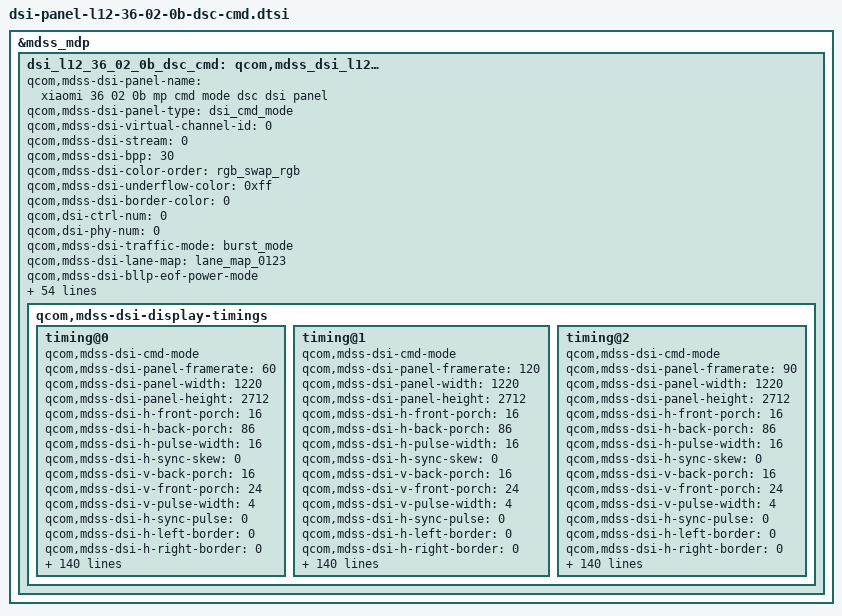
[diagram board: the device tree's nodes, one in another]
&mdss_mdp {
	dsi_l12_36_02_0b_dsc_cmd: qcom,mdss_dsi_l12_36_02_0b_dsc_cmd {
		qcom,mdss-dsi-panel-name = "xiaomi 36 02 0b mp cmd mode dsc dsi panel";
		qcom,mdss-dsi-panel-type = "dsi_cmd_mode";
		qcom,mdss-dsi-virtual-channel-id = <0>;
		qcom,mdss-dsi-stream = <0>;
		qcom,mdss-dsi-bpp = <30>;
		qcom,mdss-dsi-color-order = "rgb_swap_rgb";
		qcom,mdss-dsi-underflow-color = <0xff>;
		qcom,mdss-dsi-border-color = <0>;

		qcom,dsi-ctrl-num = <0>;
		qcom,dsi-phy-num = <0>;

		qcom,mdss-dsi-traffic-mode = "burst_mode";
		qcom,mdss-dsi-lane-map = "lane_map_0123";
		qcom,mdss-dsi-bllp-eof-power-mode;
		qcom,mdss-dsi-bllp-power-mode;
		qcom,mdss-dsi-lane-0-state;
		qcom,mdss-dsi-lane-1-state;
		qcom,mdss-dsi-lane-2-state;
		qcom,mdss-dsi-lane-3-state;
		qcom,mdss-dsi-dma-trigger = "trigger_sw";
		qcom,mdss-dsi-mdp-trigger = "none";
		qcom,mdss-dsi-reset-sequence =  <1 11>, <0 1>, <1 11>;
		qcom,mdss-pan-physical-width-dimension = <695>;
		qcom,mdss-pan-physical-height-dimension = <1545>;
		qcom,mdss-dsi-te-pin-select = <1>;
		qcom,mdss-dsi-wr-mem-start = <0x2c>;
		qcom,mdss-dsi-wr-mem-continue = <0x3c>;
		qcom,mdss-dsi-te-dcs-command = <1>;
		qcom,mdss-dsi-te-check-enable;
		qcom,mdss-dsi-te-using-te-pin;
		qcom,mdss-dsi-tx-eot-append;
		qcom,mdss-dsi-lp11-init;

		qcom,mdss-dsi-bl-inverted-dbv;
		qcom,bl-update-flag = "delay_until_first_frame";
		qcom,mdss-dsi-panel-mode-switch;

		qcom,mdss-dsi-panel-hdr-enabled;
		qcom,mdss-dsi-panel-hdr-color-primaries = <14500 15500 32000 17000 15500 30000 8000 3000>;
		qcom,mdss-dsi-panel-peak-brightness = <4200000>;
		qcom,mdss-dsi-panel-blackness-level = <3230>;
		qcom,mdss-dsi-dma-schedule-line = <1>;
		qcom,mdss-dsi-dma-schedule-window = <10>;

		qcom,mdss-dsi-display-timings {
			/* 60 Hz */
			timing@0{
				qcom,mdss-dsi-cmd-mode;
				qcom,mdss-dsi-panel-framerate = <60>;
				qcom,mdss-dsi-panel-width = <1220>;
				qcom,mdss-dsi-panel-height = <2712>;
				qcom,mdss-dsi-h-front-porch = <16>;
				qcom,mdss-dsi-h-back-porch = <86>;
				qcom,mdss-dsi-h-pulse-width = <16>;
				qcom,mdss-dsi-h-sync-skew = <0>;
				qcom,mdss-dsi-v-back-porch = <16>;
				qcom,mdss-dsi-v-front-porch = <24>;
				qcom,mdss-dsi-v-pulse-width = <4>;
				qcom,mdss-dsi-h-sync-pulse = <0>;
				qcom,mdss-dsi-h-left-border = <0>;
				qcom,mdss-dsi-h-right-border = <0>;
				qcom,mdss-dsi-v-top-border = <0>;
				qcom,mdss-dsi-v-bottom-border = <0>;
				qcom,mdss-dsi-panel-clockrate = <1100000000>;
				qcom,mdss-dsi-panel-jitter = <0x5 0x1>;
				qcom,mdss-mdp-transfer-time-us = <7300>;
				qcom,mdss-dsi-on-command = [
					/* common OD code */
					39 00 00 00 00 00 06 F0 55 AA 52 08 08
					39 00 00 40 00 00 06 E0 41 73 73 73 83
					39 00 00 40 00 00 16 E1
						00 00 00 00 00 00 00 00 00 00 00 00 00 00 00 00
						00 00 00 00 00
					39 00 00 40 00 00 16 E2
						80 EF 66 86 00 00 00 00 00 00 00 00 00 00 00 00
						00 00 02 01 00
					39 00 00 40 00 00 16 E3
						00 00 00 00 00 00 00 00 00 00 00 00 00 00 00 00
						00 00 00 00 00
					39 00 00 40 00 00 13 E4
						00 00 00 00 00 00 00 00 00 00 00 00 00 00 00 00
						00 00
					39 00 00 40 00 00 13 E5
						00 00 00 00 00 00 00 00 00 00 00 00 00 00 00 00
						00 00
					39 00 00 00 00 00 13 E6
						00 00 00 00 00 00 00 00 00 00 00 00 00 00 00 00
						00 00
					39 00 00 40 00 00 06 F0 55 AA 52 08 07
					15 00 00 40 00 00 02 6F 37
					39 00 00 40 00 00 04 B7 08 08 08
					39 00 00 40 00 00 06 F0 55 AA 52 08 00
					15 00 00 40 00 00 02 6F 37
					39 00 00 40 00 00 04 B7 08 08 08
					39 00 00 40 00 00 06 F0 55 AA 52 08 00
					15 00 00 40 00 00 02 6F 01
					15 00 00 40 00 00 02 C0 20
					39 00 00 40 00 00 06 F0 55 AA 52 08 08
					39 00 00 40 00 00 22 EA
						02 00 E0 00 E0 70 00 70 00 00 00 00 00 00 00 00
						00 00 00 00 00 00 00 00 00 00 00 00 00 00 00 00
						00
					15 00 00 40 00 00 02 6F 15
					39 00 00 40 00 00 07 EA 00 00 80 00 80 00
					39 00 00 40 00 00 06 F0 55 AA 52 08 08
					15 00 00 40 00 00 02 6F 21
					39 00 00 00 00 00 07 EA 00 00 00 00 00 00
					/* 60Hz OD code */
					39 00 00 40 00 00 06 F0 55 AA 52 08 08
					15 00 00 40 00 00 02 E0 01
					39 00 00 40 00 00 05 E2 88 E0 CC 0C
					15 00 00 40 00 00 02 6F 12
					39 00 00 40 00 00 03 E2 86 01
					39 00 00 40 00 00 09 EA 02 00 E0 00 E0 70 00 70
					15 00 00 40 00 00 02 6F 17
					39 00 00 00 00 00 04 EA 80 00 80
					/* Enable EMIT real-time Reset */
					39 00 00 40 00 00 06 F0 55 AA 52 08 00
					15 00 00 40 00 00 02 6F 13
					15 00 00 00 00 00 02 B2 4F
					/* Write time detection */
					39 00 00 40 00 00 05 FF AA 55 A5 81
					15 00 00 40 00 00 02 6F 19
					15 00 00 40 00 00 02 FB 00
					15 00 00 40 00 00 02 6F 05
					15 00 00 00 00 00 02 FE 34
					/* VGMP */
					39 00 00 40 00 00 05 FF AA 55 A5 80
					15 00 00 40 00 00 02 6F 1A
					15 00 00 40 00 00 02 F4 55
					15 00 00 40 00 00 02 6F 0F
					15 00 00 40 00 00 02 fc 00
					15 00 00 40 00 00 02 6F 09
					39 00 00 00 00 00 03 Fc FC F0
					/* SRAM */
					39 00 00 40 00 00 05 FF AA 55 A5 83
					15 00 00 40 00 00 02 6F 12
					15 00 00 00 00 00 02 FE 41
					/* GIR OFF */
					15 00 00 40 00 00 02 5F 01
					15 00 00 40 00 00 02 26 00
					15 00 00 00 00 00 02 17 10
					/* CASET/RASET Setting 1220*2712 */
					39 00 00 40 00 00 05 2A 00 00 04 C3
					39 00 00 00 00 00 05 2B 00 00 0A 97
					/* 60 Hz */
					15 00 00 00 00 00 02 2F 00
					/* TE ON */
					15 00 00 40 00 00 02 35 30
					39 00 00 40 00 00 03 44 00 00
					39 00 00 40 00 00 03 51 00 00
					15 00 00 40 00 00 02 6F 04
					39 00 00 40 00 00 03 51 03 FF
					15 00 00 00 00 00 02 53 20
					/* DSC Setting */
					15 00 00 40 00 00 02 90 03
					39 00 00 40 00 00 13 91
						AB 28 00 0C D2 00 02 4C 01 24 00 08 09 75 07 7B
						10 F0
					39 00 00 40 00 00 05 FF AA 55 A5 81
					15 00 00 40 00 00 02 6F 0B
					15 00 00 40 00 00 02 FD 80
					39 00 00 40 00 00 05 FF AA 55 A5 81
					15 00 00 40 00 00 02 6F 0E
					15 00 00 00 00 00 02 F5 00
					/* OSC=127.9525M */
					39 00 00 40 00 00 05 FF AA 55 A5 80
					15 00 00 40 00 00 02 6F 15
					39 00 00 40 00 00 03 F8 01 68
					15 00 00 40 00 00 02 6F 31
					39 00 00 40 00 00 03 F8 01 0E
					15 00 00 40 00 00 02 6F 01
					15 00 00 00 00 00 02 1F 06
					/* Video trim */
					39 00 00 40 00 00 05 FF AA 55 A5 80
					15 00 00 40 00 00 02 6F 31
					39 00 00 40 00 00 03 F8 01 0C
					39 00 00 40 00 00 05 FF AA 55 A5 80
					15 00 00 40 00 00 02 6F 15
					39 00 00 40 00 00 03 F8 01 5F
					39 00 00 40 00 00 06 F0 55 AA 52 08 01
					39 00 00 00 00 00 2A C3
						DD 06 22 11 FF 00 06 20 11 FF 00 04 01 11 05 95
						18 04 01 11 05 95 18 04 01 11 05 95 18 04 01 11
						05 95 18 04 01 11 05 95 18
					/* ESD Error Flag, Normal High, Error Low */
					39 00 00 40 00 00 06 F0 55 AA 52 08 00
					39 00 00 40 00 00 02 6F 01
					39 00 00 40 00 00 02 BE 45
					39 00 00 40 00 00 02 6F 05
					39 00 00 00 00 00 02 BE 88
					/* dimming step timing */
					39 01 00 40 00 00 06 F0 55 AA 52 08 00
					15 01 00 40 00 00 02 B2 09
					15 01 00 40 00 00 02 6F 05
					39 01 00 00 00 00 03 B2 08 08
					/* AOD Flicker Not P2 batch need to add*/
					39 00 00 40 00 00 06 F0 55 AA 52 08 00
					15 00 00 40 00 00 02 E2 40
					15 00 00 40 00 00 02 6F 57
					39 00 00 40 00 00 06 E2 FF FF FF FF FF
					15 00 00 40 00 00 02 6F 37
					39 00 00 00 00 00 05 E2 80 08 08 0C
					/* TM Dotted line */
					39 00 00 40 00 00 06 F0 55 AA 52 08 01
					15 00 00 00 00 00 02 DD 40
					/* TM-DSOP-OFF */
					39 00 00 40 00 00 06 F0 55 AA 52 08 00
					39 00 00 00 00 00 11 C6
						AD AA AA A3 AD AA AA A3 AD AA AA A3 AD AA AA A3
					/* Power Off Regulator Timing */
					39 00 00 40 00 00 05 FF AA 55 A5 80
					15 00 00 40 00 00 02 6F 0A
					39 00 00 40 00 00 04 F6 70 70 70
					15 00 00 40 00 00 02 6F 0E
					15 00 00 40 00 00 02 F6 70
					/* AOD On/Off Speed Up */
					15 00 00 40 00 00 02 6F 2D
					15 00 00 00 00 00 02 FC 44
					39 00 00 40 00 00 06 F0 55 AA 52 08 01
					15 00 00 40 00 00 02 6F 01
					39 00 00 40 00 00 05 D2 00 00 00 20
					39 00 00 40 00 00 04 E4 80 05 5C
					15 00 00 40 00 00 02 6F 07
					39 00 00 40 00 00 03 E4 05 5C
					15 00 00 40 00 00 02 6F 0A
					39 00 00 40 00 00 04 E4 80 05 5C
					15 00 00 40 00 00 02 6F 21
					39 00 00 40 00 00 04 D8 60 60 60
					/* VGL_REG shift 1/2 Frame */
					15 00 00 40 00 00 02 6F 1E
					15 00 00 40 00 00 02 D8 24
					/* //PVDD&PVEE OFF Shift 1 Frame */
					15 00 00 00 00 00 02 CD 61
					/* GOA power on/off Timing */
					39 00 00 40 00 00 06 F0 55 AA 52 08 05
					39 00 00 40 00 00 03 B3 84 85
					39 00 00 40 00 00 03 B5 84 85
					39 00 00 40 00 00 05 B7 84 00 00 84
					39 00 00 00 00 00 05 B8 84 00 00 84
					/* Power Off Frame */
					39 00 00 40 00 00 06 F0 55 AA 52 08 00
					15 00 00 40 00 00 02 6F 07
					39 00 00 00 00 00 04 CA 08 06 58
					/* Display on */
					05 00 00 00 78 00 02 11 00
					05 00 00 00 00 00 02 29 00
				];
				qcom,mdss-dsi-off-command = [
					05 00 00 00 00 00 02 28 00
					05 00 00 00 64 00 02 10 00
				];
				qcom,mdss-dsi-on-command-state = "dsi_lp_mode";
				qcom,mdss-dsi-off-command-state = "dsi_lp_mode";

				qcom,mdss-dsi-timing-switch-command = [
					/* 60 Hz */
					15 00 00 00 00 00 02 2F 00
					/* 60Hz OD code */
					39 00 00 40 00 00 06 F0 55 AA 52 08 08
					15 00 00 40 00 00 02 E0 01
					39 00 00 40 00 00 05 E2 88 E0 CC 0C
					15 00 00 40 00 00 02 6F 12
					39 00 00 40 00 00 03 E2 86 01
					39 00 00 40 00 00 09 EA 02 00 E0 00 E0 70 00 70
					15 00 00 40 00 00 02 6F 17
					39 00 00 00 00 00 04 EA 80 00 80
				];
				qcom,mdss-dsi-timing-switch-command-update = <0x2F 0 1>;
				qcom,mdss-dsi-timing-switch-command-state = "dsi_hs_mode";

				qcom,mdss-dsi-nolp-command = [
					/* Enable osc trim */
					39 00 00 00 00 00 06 F0 55 AA 52 08 01
					15 00 00 00 00 00 02 C3 DD
					/*AOD Mode off*/
					15 00 00 00 00 00 02 65 00
					15 00 00 00 00 00 02 38 00
					39 00 00 00 00 00 07 51 00 00 00 00 03 FF
					15 00 00 00 00 00 02 2C 00
					/* ERR Flag enable */
					39 00 00 00 00 00 06 F0 55 AA 52 08 00
					39 00 00 00 00 00 02 6F 01
					39 00 00 00 00 00 02 BE 45
				];
				qcom,mdss-dsi-nolp-command-state = "dsi_lp_mode";

				qcom,compression-mode = "dsc";
				qcom,mdss-dsc-config-by-manufacture-cmd;
				qcom,mdss-dsc-version = <0x11>;
				qcom,mdss-dsc-scr-version = <0x1>;
				qcom,mdss-dsc-slice-height = <12>;
				qcom,mdss-dsc-slice-width = <610>;
				qcom,mdss-dsc-slice-per-pkt = <2>;
				qcom,mdss-dsc-bit-per-component = <10>;
				qcom,mdss-dsc-bit-per-pixel = <8>;
				qcom,mdss-dsc-block-prediction-enable;
			};
			/* 120 Hz */
			timing@1{
				qcom,mdss-dsi-cmd-mode;
				qcom,mdss-dsi-panel-framerate = <120>;
				qcom,mdss-dsi-panel-width = <1220>;
				qcom,mdss-dsi-panel-height = <2712>;
				qcom,mdss-dsi-h-front-porch = <16>;
				qcom,mdss-dsi-h-back-porch = <86>;
				qcom,mdss-dsi-h-pulse-width = <16>;
				qcom,mdss-dsi-h-sync-skew = <0>;
				qcom,mdss-dsi-v-back-porch = <16>;
				qcom,mdss-dsi-v-front-porch = <24>;
				qcom,mdss-dsi-v-pulse-width = <4>;
				qcom,mdss-dsi-h-sync-pulse = <0>;
				qcom,mdss-dsi-h-left-border = <0>;
				qcom,mdss-dsi-h-right-border = <0>;
				qcom,mdss-dsi-v-top-border = <0>;
				qcom,mdss-dsi-v-bottom-border = <0>;
				qcom,mdss-dsi-panel-clockrate = <1100000000>;
				qcom,mdss-dsi-panel-jitter = <0x5 0x1>;
				qcom,mdss-mdp-transfer-time-us = <7300>;
				qcom,mdss-dsi-on-command = [
					/* common OD code */
					39 00 00 00 00 00 06 F0 55 AA 52 08 08
					39 00 00 40 00 00 06 E0 41 73 73 73 83
					39 00 00 40 00 00 16 E1
						00 00 00 00 00 00 00 00 00 00 00 00 00 00 00 00
						00 00 00 00 00
					39 00 00 40 00 00 16 E2
						80 EF 66 86 00 00 00 00 00 00 00 00 00 00 00 00
						00 00 02 01 00
					39 00 00 40 00 00 16 E3
						00 00 00 00 00 00 00 00 00 00 00 00 00 00 00 00
						00 00 00 00 00
					39 00 00 40 00 00 13 E4
						00 00 00 00 00 00 00 00 00 00 00 00 00 00 00 00
						00 00
					39 00 00 40 00 00 13 E5
						00 00 00 00 00 00 00 00 00 00 00 00 00 00 00 00
						00 00
					39 00 00 00 00 00 13 E6
						00 00 00 00 00 00 00 00 00 00 00 00 00 00 00 00
						00 00
					39 00 00 40 00 00 06 F0 55 AA 52 08 07
					15 00 00 40 00 00 02 6F 37
					39 00 00 40 00 00 04 B7 08 08 08
					39 00 00 40 00 00 06 F0 55 AA 52 08 00
					15 00 00 40 00 00 02 6F 37
					39 00 00 40 00 00 04 B7 08 08 08
					39 00 00 40 00 00 06 F0 55 AA 52 08 00
					15 00 00 40 00 00 02 6F 01
					15 00 00 40 00 00 02 C0 20
					39 00 00 40 00 00 06 F0 55 AA 52 08 08
					39 00 00 40 00 00 22 EA
						02 00 E0 00 E0 70 00 70 00 00 00 00 00 00 00 00
						00 00 00 00 00 00 00 00 00 00 00 00 00 00 00 00
						00
					15 00 00 40 00 00 02 6F 15
					39 00 00 40 00 00 07 EA 00 00 80 00 80 00
					39 00 00 40 00 00 06 F0 55 AA 52 08 08
					15 00 00 40 00 00 02 6F 21
					39 00 00 00 00 00 07 EA 00 00 00 00 00 00
					/* 120Hz OD code */
					39 00 00 40 00 00 06 F0 55 AA 52 08 08
					15 00 00 40 00 00 02 E0 01
					39 00 00 40 00 00 05 E2 D6 4E 84 88
					15 00 00 40 00 00 02 6F 12
					39 00 00 40 00 00 03 E2 FD 03
					39 00 00 40 00 00 09 EA 02 00 E0 00 E0 80 00 80
					15 00 00 40 00 00 02 6F 17
					39 00 00 00 00 00 04 EA 38 00 38
					/* Enable EMIT real-time Reset */
					39 00 00 40 00 00 06 F0 55 AA 52 08 00
					15 00 00 40 00 00 02 6F 13
					15 00 00 00 00 00 02 B2 4F
					/* Write time detection */
					39 00 00 40 00 00 05 FF AA 55 A5 81
					15 00 00 40 00 00 02 6F 19
					15 00 00 40 00 00 02 FB 00
					15 00 00 40 00 00 02 6F 05
					15 00 00 00 00 00 02 FE 34
					/* VGMP */
					39 00 00 40 00 00 05 FF AA 55 A5 80
					15 00 00 40 00 00 02 6F 1A
					15 00 00 40 00 00 02 F4 55
					15 00 00 40 00 00 02 6F 0F
					15 00 00 40 00 00 02 fc 00
					15 00 00 40 00 00 02 6F 09
					39 00 00 00 00 00 03 Fc FC F0
					/* SRAM */
					39 00 00 40 00 00 05 FF AA 55 A5 83
					15 00 00 40 00 00 02 6F 12
					15 00 00 00 00 00 02 FE 41
					/* GIR OFF */
					15 00 00 40 00 00 02 5F 01
					15 00 00 40 00 00 02 26 00
					15 00 00 00 00 00 02 17 10
					/* CASET/RASET Setting 1220*2712 */
					39 00 00 40 00 00 05 2A 00 00 04 C3
					39 00 00 00 00 00 05 2B 00 00 0A 97
					/* 120 Hz */
					15 00 00 00 00 00 02 2F 02
					/* TE ON */
					15 00 00 40 00 00 02 35 30
					39 00 00 40 00 00 03 44 00 00
					39 00 00 40 00 00 03 51 00 00
					15 00 00 40 00 00 02 6F 04
					39 00 00 40 00 00 03 51 03 FF
					15 00 00 00 00 00 02 53 20
					/* DSC Setting */
					15 00 00 40 00 00 02 90 03
					39 00 00 40 00 00 13 91
						AB 28 00 0C D2 00 02 4C 01 24 00 08 09 75 07 7B
						10 F0
					39 00 00 40 00 00 05 FF AA 55 A5 81
					15 00 00 40 00 00 02 6F 0B
					15 00 00 40 00 00 02 FD 80
					39 00 00 40 00 00 05 FF AA 55 A5 81
					15 00 00 40 00 00 02 6F 0E
					15 00 00 00 00 00 02 F5 00
					/* OSC=127.9525M */
					39 00 00 40 00 00 05 FF AA 55 A5 80
					15 00 00 40 00 00 02 6F 15
					39 00 00 40 00 00 03 F8 01 68
					15 00 00 40 00 00 02 6F 31
					39 00 00 40 00 00 03 F8 01 0E
					15 00 00 40 00 00 02 6F 01
					15 00 00 00 00 00 02 1F 06
					/* Video trim */
					39 00 00 40 00 00 05 FF AA 55 A5 80
					15 00 00 40 00 00 02 6F 31
					39 00 00 40 00 00 03 F8 01 0C
					39 00 00 40 00 00 05 FF AA 55 A5 80
					15 00 00 40 00 00 02 6F 15
					39 00 00 40 00 00 03 F8 01 5F
					39 00 00 40 00 00 06 F0 55 AA 52 08 01
					39 00 00 00 00 00 2A C3
						DD 06 22 11 FF 00 06 20 11 FF 00 04 01 11 05 95
						18 04 01 11 05 95 18 04 01 11 05 95 18 04 01 11
						05 95 18 04 01 11 05 95 18
					/* ESD Error Flag, Normal High, Error Low */
					39 00 00 40 00 00 06 F0 55 AA 52 08 00
					39 00 00 40 00 00 02 6F 01
					39 00 00 40 00 00 02 BE 45
					39 00 00 40 00 00 02 6F 05
					39 00 00 00 00 00 02 BE 88
					/* dimming step timing */
					39 00 00 40 00 00 06 F0 55 AA 52 08 00
					15 00 00 40 00 00 02 B2 09
					15 00 00 40 00 00 02 6F 05
					39 00 00 00 00 00 03 B2 08 08
					/* AOD Flicker Not P2 batch need to add*/
					39 00 00 40 00 00 06 F0 55 AA 52 08 00
					15 00 00 40 00 00 02 E2 40
					15 00 00 40 00 00 02 6F 57
					39 00 00 40 00 00 06 E2 FF FF FF FF FF
					15 00 00 40 00 00 02 6F 37
					39 00 00 00 00 00 05 E2 80 08 08 0C
					/* TM Dotted line */
					39 00 00 40 00 00 06 F0 55 AA 52 08 01
					15 00 00 00 00 00 02 DD 40
					/* TM-DSOP-OFF */
					39 00 00 40 00 00 06 F0 55 AA 52 08 00
					39 00 00 00 00 00 11 C6
						AD AA AA A3 AD AA AA A3 AD AA AA A3 AD AA AA A3
					/* Power Off Regulator Timing */
					39 00 00 40 00 00 05 FF AA 55 A5 80
					15 00 00 40 00 00 02 6F 0A
					39 00 00 40 00 00 04 F6 70 70 70
					15 00 00 40 00 00 02 6F 0E
					15 00 00 40 00 00 02 F6 70
					/* AOD On/Off Speed Up */
					15 00 00 40 00 00 02 6F 2D
					15 00 00 00 00 00 02 FC 44
					39 00 00 40 00 00 06 F0 55 AA 52 08 01
					15 00 00 40 00 00 02 6F 01
					39 00 00 40 00 00 05 D2 00 00 00 20
					39 00 00 40 00 00 04 E4 80 05 5C
					15 00 00 40 00 00 02 6F 07
					39 00 00 40 00 00 03 E4 05 5C
					15 00 00 40 00 00 02 6F 0A
					39 00 00 40 00 00 04 E4 80 05 5C
					15 00 00 40 00 00 02 6F 21
					39 00 00 40 00 00 04 D8 60 60 60
					/* VGL_REG shift 1/2 Frame */
					15 00 00 40 00 00 02 6F 1E
					15 00 00 40 00 00 02 D8 24
					/* //PVDD&PVEE OFF Shift 1 Frame */
					15 00 00 00 00 00 02 CD 61
					/* GOA power on/off Timing */
					39 00 00 40 00 00 06 F0 55 AA 52 08 05
					39 00 00 40 00 00 03 B3 84 85
					39 00 00 40 00 00 03 B5 84 85
					39 00 00 40 00 00 05 B7 84 00 00 84
					39 00 00 00 00 00 05 B8 84 00 00 84
					/* Power Off Frame */
					39 00 00 40 00 00 06 F0 55 AA 52 08 00
					15 00 00 40 00 00 02 6F 07
					39 00 00 00 00 00 04 CA 08 06 58
					/* Display on */
					05 00 00 00 78 00 02 11 00
					05 00 00 00 00 00 02 29 00
				];
				qcom,mdss-dsi-off-command = [
					05 00 00 00 00 00 02 28 00
					05 00 00 00 64 00 02 10 00
				];
				qcom,mdss-dsi-on-command-state = "dsi_lp_mode";
				qcom,mdss-dsi-off-command-state = "dsi_lp_mode";

				qcom,mdss-dsi-timing-switch-command = [
					/* 120 Hz */
					15 00 00 00 00 00 02 2F 02
					/* 120Hz OD code */
					39 00 00 40 00 00 06 F0 55 AA 52 08 08
					15 00 00 40 00 00 02 E0 01
					39 00 00 40 00 00 05 E2 D6 4E 84 88
					15 00 00 40 00 00 02 6F 12
					39 00 00 40 00 00 03 E2 FD 03
					39 00 00 40 00 00 09 EA 02 00 E0 00 E0 80 00 80
					15 00 00 40 00 00 02 6F 17
					39 00 00 00 00 00 04 EA 38 00 38
				];
				qcom,mdss-dsi-timing-switch-command-update = <0x2F 0 1>;
				qcom,mdss-dsi-timing-switch-command-state = "dsi_hs_mode";

				qcom,mdss-dsi-nolp-command = [
					/* Enable osc trim */
					39 00 00 00 00 00 06 F0 55 AA 52 08 01
					15 00 00 00 00 00 02 C3 DD
					/*AOD Mode off*/
					15 00 00 00 00 00 02 65 00
					15 00 00 00 00 00 02 38 00
					39 00 00 00 00 00 07 51 00 00 00 00 03 FF
					15 00 00 00 00 00 02 2C 00
					/* ERR Flag enable */
					39 00 00 00 00 00 06 F0 55 AA 52 08 00
					39 00 00 00 00 00 02 6F 01
					39 00 00 00 00 00 02 BE 45
				];
				qcom,mdss-dsi-nolp-command-state = "dsi_lp_mode";

				qcom,compression-mode = "dsc";
				qcom,mdss-dsc-config-by-manufacture-cmd;
				qcom,mdss-dsc-version = <0x11>;
				qcom,mdss-dsc-scr-version = <0x1>;
				qcom,mdss-dsc-slice-height = <12>;
				qcom,mdss-dsc-slice-width = <610>;
				qcom,mdss-dsc-slice-per-pkt = <2>;
				qcom,mdss-dsc-bit-per-component = <10>;
				qcom,mdss-dsc-bit-per-pixel = <8>;
				qcom,mdss-dsc-block-prediction-enable;
			};
           	/* 90 Hz */
			timing@2{
				qcom,mdss-dsi-cmd-mode;
				qcom,mdss-dsi-panel-framerate = <90>;
				qcom,mdss-dsi-panel-width = <1220>;
				qcom,mdss-dsi-panel-height = <2712>;
				qcom,mdss-dsi-h-front-porch = <16>;
				qcom,mdss-dsi-h-back-porch = <86>;
				qcom,mdss-dsi-h-pulse-width = <16>;
				qcom,mdss-dsi-h-sync-skew = <0>;
				qcom,mdss-dsi-v-back-porch = <16>;
				qcom,mdss-dsi-v-front-porch = <24>;
				qcom,mdss-dsi-v-pulse-width = <4>;
				qcom,mdss-dsi-h-sync-pulse = <0>;
				qcom,mdss-dsi-h-left-border = <0>;
				qcom,mdss-dsi-h-right-border = <0>;
				qcom,mdss-dsi-v-top-border = <0>;
				qcom,mdss-dsi-v-bottom-border = <0>;
				qcom,mdss-dsi-panel-clockrate = <1100000000>;
				qcom,mdss-dsi-panel-jitter = <0x5 0x1>;
				qcom,mdss-mdp-transfer-time-us = <7300>;
				qcom,mdss-dsi-on-command = [
					/* common OD code */
					39 00 00 00 00 00 06 F0 55 AA 52 08 08
					39 00 00 40 00 00 06 E0 41 73 73 73 83
					39 00 00 40 00 00 16 E1
						00 00 00 00 00 00 00 00 00 00 00 00 00 00 00 00
						00 00 00 00 00
					39 00 00 40 00 00 16 E2
						80 EF 66 86 00 00 00 00 00 00 00 00 00 00 00 00
						00 00 02 01 00
					39 00 00 40 00 00 16 E3
						00 00 00 00 00 00 00 00 00 00 00 00 00 00 00 00
						00 00 00 00 00
					39 00 00 40 00 00 13 E4
						00 00 00 00 00 00 00 00 00 00 00 00 00 00 00 00
						00 00
					39 00 00 40 00 00 13 E5
						00 00 00 00 00 00 00 00 00 00 00 00 00 00 00 00
						00 00
					39 00 00 00 00 00 13 E6
						00 00 00 00 00 00 00 00 00 00 00 00 00 00 00 00
						00 00
					39 00 00 40 00 00 06 F0 55 AA 52 08 07
					15 00 00 40 00 00 02 6F 37
					39 00 00 40 00 00 04 B7 08 08 08
					39 00 00 40 00 00 06 F0 55 AA 52 08 00
					15 00 00 40 00 00 02 6F 37
					39 00 00 40 00 00 04 B7 08 08 08
					39 00 00 40 00 00 06 F0 55 AA 52 08 00
					15 00 00 40 00 00 02 6F 01
					15 00 00 40 00 00 02 C0 20
					39 00 00 40 00 00 06 F0 55 AA 52 08 08
					39 00 00 40 00 00 22 EA
						02 00 E0 00 E0 70 00 70 00 00 00 00 00 00 00 00
						00 00 00 00 00 00 00 00 00 00 00 00 00 00 00 00
						00
					15 00 00 40 00 00 02 6F 15
					39 00 00 40 00 00 07 EA 00 00 80 00 80 00
					39 00 00 40 00 00 06 F0 55 AA 52 08 08
					15 00 00 40 00 00 02 6F 21
					39 00 00 00 00 00 07 EA 00 00 00 00 00 00
					/* 90Hz OD code */
					39 00 00 40 00 00 06 F0 55 AA 52 08 08
					15 00 00 40 00 00 02 E0 01
					39 00 00 40 00 00 05 E2 42 EE 04 20
					15 00 00 40 00 00 02 6F 12
					39 00 00 40 00 00 03 E2 FD 03
					39 00 00 40 00 00 09 EA 02 00 B8 00 B8 58 00 58
					15 00 00 40 00 00 02 6F 17
					39 00 00 00 00 00 04 EA 48 00 48
					/* Enable EMIT real-time Reset */
					39 00 00 40 00 00 06 F0 55 AA 52 08 00
					15 00 00 40 00 00 02 6F 13
					15 00 00 00 00 00 02 B2 4F
					/* Write time detection */
					39 00 00 40 00 00 05 FF AA 55 A5 81
					15 00 00 40 00 00 02 6F 19
					15 00 00 40 00 00 02 FB 00
					15 00 00 40 00 00 02 6F 05
					15 00 00 00 00 00 02 FE 34
					/* VGMP */
					39 00 00 40 00 00 05 FF AA 55 A5 80
					15 00 00 40 00 00 02 6F 1A
					15 00 00 40 00 00 02 F4 55
					15 00 00 40 00 00 02 6F 0F
					15 00 00 40 00 00 02 fc 00
					15 00 00 40 00 00 02 6F 09
					39 00 00 00 00 00 03 Fc FC F0
					/* SRAM */
					39 00 00 40 00 00 05 FF AA 55 A5 83
					15 00 00 40 00 00 02 6F 12
					15 00 00 00 00 00 02 FE 41
					/* GIR OFF */
					15 00 00 40 00 00 02 5F 01
					15 00 00 40 00 00 02 26 00
					15 00 00 00 00 00 02 17 10
					/* CASET/RASET Setting 1220*2712 */
					39 00 00 40 00 00 05 2A 00 00 04 C3
					39 00 00 00 00 00 05 2B 00 00 0A 97
					/* 90 Hz */
					15 00 00 00 00 00 02 2F 01
					/* TE ON */
					15 00 00 40 00 00 02 35 30
					39 00 00 40 00 00 03 44 00 00
					39 00 00 40 00 00 03 51 00 00
					15 00 00 40 00 00 02 6F 04
					39 00 00 40 00 00 03 51 03 FF
					15 00 00 00 00 00 02 53 20
					/* DSC Setting */
					15 00 00 40 00 00 02 90 03
					39 00 00 40 00 00 13 91
						AB 28 00 0C D2 00 02 4C 01 24 00 08 09 75 07 7B
						10 F0
					39 00 00 40 00 00 05 FF AA 55 A5 81
					15 00 00 40 00 00 02 6F 0B
					15 00 00 40 00 00 02 FD 80
					39 00 00 40 00 00 05 FF AA 55 A5 81
					15 00 00 40 00 00 02 6F 0E
					15 00 00 00 00 00 02 F5 00
					/* OSC=127.9525M */
					39 00 00 40 00 00 05 FF AA 55 A5 80
					15 00 00 40 00 00 02 6F 15
					39 00 00 40 00 00 03 F8 01 68
					15 00 00 40 00 00 02 6F 31
					39 00 00 40 00 00 03 F8 01 0E
					15 00 00 40 00 00 02 6F 01
					15 00 00 00 00 00 02 1F 06
					/* Video trim */
					39 00 00 40 00 00 05 FF AA 55 A5 80
					15 00 00 40 00 00 02 6F 31
					39 00 00 40 00 00 03 F8 01 0C
					39 00 00 40 00 00 05 FF AA 55 A5 80
					15 00 00 40 00 00 02 6F 15
					39 00 00 40 00 00 03 F8 01 5F
					39 00 00 40 00 00 06 F0 55 AA 52 08 01
					39 00 00 00 00 00 2A C3
						DD 06 22 11 FF 00 06 20 11 FF 00 04 01 11 05 95
						18 04 01 11 05 95 18 04 01 11 05 95 18 04 01 11
						05 95 18 04 01 11 05 95 18
					/* ESD Error Flag, Normal High, Error Low */
					39 00 00 40 00 00 06 F0 55 AA 52 08 00
					39 00 00 40 00 00 02 6F 01
					39 00 00 40 00 00 02 BE 45
					39 00 00 40 00 00 02 6F 05
					39 00 00 00 00 00 02 BE 88
					/* dimming step timing */
					39 01 00 40 00 00 06 F0 55 AA 52 08 00
					15 01 00 40 00 00 02 B2 09
					15 01 00 40 00 00 02 6F 05
					39 01 00 00 00 00 03 B2 08 08
					/* AOD Flicker Not P2 batch need to add*/
					39 00 00 40 00 00 06 F0 55 AA 52 08 00
					15 00 00 40 00 00 02 E2 40
					15 00 00 40 00 00 02 6F 57
					39 00 00 40 00 00 06 E2 FF FF FF FF FF
					15 00 00 40 00 00 02 6F 37
					39 00 00 00 00 00 05 E2 80 08 08 0C
					/* TM Dotted line */
					39 00 00 40 00 00 06 F0 55 AA 52 08 01
					15 00 00 00 00 00 02 DD 40
					/* TM-DSOP-OFF */
					39 00 00 40 00 00 06 F0 55 AA 52 08 00
					39 00 00 00 00 00 11 C6
						AD AA AA A3 AD AA AA A3 AD AA AA A3 AD AA AA A3
					/* Power Off Regulator Timing */
					39 00 00 40 00 00 05 FF AA 55 A5 80
					15 00 00 40 00 00 02 6F 0A
					39 00 00 40 00 00 04 F6 70 70 70
					15 00 00 40 00 00 02 6F 0E
					15 00 00 40 00 00 02 F6 70
					/* AOD On/Off Speed Up */
					15 00 00 40 00 00 02 6F 2D
					15 00 00 00 00 00 02 FC 44
					39 00 00 40 00 00 06 F0 55 AA 52 08 01
					15 00 00 40 00 00 02 6F 01
					39 00 00 40 00 00 05 D2 00 00 00 20
					39 00 00 40 00 00 04 E4 80 05 5C
					15 00 00 40 00 00 02 6F 07
					39 00 00 40 00 00 03 E4 05 5C
					15 00 00 40 00 00 02 6F 0A
					39 00 00 40 00 00 04 E4 80 05 5C
					15 00 00 40 00 00 02 6F 21
					39 00 00 40 00 00 04 D8 60 60 60
					/* VGL_REG shift 1/2 Frame */
					15 00 00 40 00 00 02 6F 1E
					15 00 00 40 00 00 02 D8 24
					/* //PVDD&PVEE OFF Shift 1 Frame */
					15 00 00 00 00 00 02 CD 61
					/* GOA power on/off Timing */
					39 00 00 40 00 00 06 F0 55 AA 52 08 05
					39 00 00 40 00 00 03 B3 84 85
					39 00 00 40 00 00 03 B5 84 85
					39 00 00 40 00 00 05 B7 84 00 00 84
					39 00 00 00 00 00 05 B8 84 00 00 84
					/* Power Off Frame */
					39 00 00 40 00 00 06 F0 55 AA 52 08 00
					15 00 00 40 00 00 02 6F 07
					39 00 00 00 00 00 04 CA 08 06 58
					/* Display on */
					05 00 00 00 78 00 02 11 00
					05 00 00 00 00 00 02 29 00
				];
				qcom,mdss-dsi-off-command = [
					05 00 00 00 00 00 02 28 00
					05 00 00 00 64 00 02 10 00
				];
				qcom,mdss-dsi-on-command-state = "dsi_lp_mode";
				qcom,mdss-dsi-off-command-state = "dsi_lp_mode";

				qcom,mdss-dsi-timing-switch-command = [
					/* 90 Hz */
					15 00 00 00 00 00 02 2F 01
					/* 90Hz OD code */
					39 00 00 40 00 00 06 F0 55 AA 52 08 08
					15 00 00 40 00 00 02 E0 01
					39 00 00 40 00 00 05 E2 42 EE 04 20
					15 00 00 40 00 00 02 6F 12
					39 00 00 40 00 00 03 E2 FD 03
					39 00 00 40 00 00 09 EA 02 00 B8 00 B8 58 00 58
					15 00 00 40 00 00 02 6F 17
					39 00 00 00 00 00 04 EA 48 00 48
				];
				qcom,mdss-dsi-timing-switch-command-update = <0x2F 0 1>;
				qcom,mdss-dsi-timing-switch-command-state = "dsi_hs_mode";

				qcom,mdss-dsi-nolp-command = [
					/* Enable osc trim */
					39 00 00 00 00 00 06 F0 55 AA 52 08 01
					15 00 00 00 00 00 02 C3 DD
					/*AOD Mode off*/
					15 00 00 00 00 00 02 65 00
					15 00 00 00 00 00 02 38 00
					39 00 00 00 00 00 07 51 00 00 00 00 03 FF
					15 00 00 00 00 00 02 2C 00
					/* ERR Flag enable */
					39 00 00 00 00 00 06 F0 55 AA 52 08 00
					39 00 00 00 00 00 02 6F 01
					39 00 00 00 00 00 02 BE 45
				];
				qcom,mdss-dsi-nolp-command-state = "dsi_lp_mode";

				qcom,compression-mode = "dsc";
				qcom,mdss-dsc-config-by-manufacture-cmd;
				qcom,mdss-dsc-version = <0x11>;
				qcom,mdss-dsc-scr-version = <0x1>;
				qcom,mdss-dsc-slice-height = <12>;
				qcom,mdss-dsc-slice-width = <610>;
				qcom,mdss-dsc-slice-per-pkt = <2>;
				qcom,mdss-dsc-bit-per-component = <10>;
				qcom,mdss-dsc-bit-per-pixel = <8>;
				qcom,mdss-dsc-block-prediction-enable;
			};
		};
	};
};

&dsi_l12_36_02_0b_dsc_cmd {
	mi,panel-id = <0x004C3132 0x00360200>;

	/* IRQF_ONESHOT | IRQF_TRIGGER_LOW */
	mi,esd-err-irq-gpio = <&tlmm 116 0x2008>;

	mi,thermal-dimming-flag;
	mi,panel-on-dimming-delay = <120>;
	mi,dimming-need-update-speed;
	mi,dimming-node = <0 200 450 800 4095>;

	mi,max-brightness-clone = <4095>;
	mi,normal-max-brightness-clone = <2047>;
	mi,mdss-dsi-fac-bl-max-level = <2047>;
	mi,mdss-fac-brightness-max-level = <2047>;
	mi,hbm-bl-min-level = <1>;
	mi,hbm-bl-max-level = <2047>;

	mi,local-hbm-enabled;
	mi,local-hbm-white-1000nit-update-flag;
	mi,local-hbm-white-110nit-update-flag;
	mi,local-hbm-alpha-ctrl-aa-area;
	mi,local-hbm-ctrl-df-reg;

	mi,doze-hbm-dbv-level = <252>;
	mi,doze-lbm-dbv-level = <20>;
	mi,ddic-round-corner-enabled;

	mi,fod-low-brightness-clone-threshold = <200>;
	mi,fod-low-brightness-lux-threshold = <3>;

	mi,flat-update-flag;
	mi,flat-need-sync-te;
	/* if gamma updated status cfg is 0x00, need to config */
	mi,flat-need-update-gamma-zero;

	mi,local-hbm-ui-ready-delay-num-frame = <4>; /* 4 frame */

	qcom,mdss-dsi-display-timings {
		timing@0{ /* 60 hz */
			/*<flat on gamma, flat off gamma>*/
			mi,mdss-flat-status-control-gamma-cfg = <0x03 0x00>;
			mi,mdss-dsi-dimmingon-command = [39 00 00 00 00 00 02 53 28];
			mi,mdss-dsi-dimmingon-command-state = "dsi_hs_mode";
			mi,mdss-dsi-dimmingoff-command = [39 00 00 00 00 00 02 53 20];
			mi,mdss-dsi-dimmingoff-command-state = "dsi_hs_mode";

			mi,mdss-dsi-hbm-fod-on-command = [
				39 00 00 00 00 00 05 51 0F FF 00 00];
			mi,mdss-dsi-hbm-fod-on-command-state = "dsi_lp_mode";
			mi,mdss-dsi-hbm-fod-off-command = [
				39 00 00 00 00 00 05 51 07 FF 00 00];
			mi,mdss-dsi-hbm-fod-off-command-state = "dsi_lp_mode";
			mi,mdss-dsi-hbm-fod-off-command-update = <0x51 0 2>;

			mi,mdss-dsi-local-hbm-normal-white-1000nit-command = [
				39 00 00 40 00 00 06 F0 55 AA 52 08 00
				39 00 00 40 00 00 02 6F 31
				39 00 00 40 00 00 02 DF 22
				39 00 00 40 00 00 06 F0 55 AA 52 08 02
				/*FPR area RGB[11:0] setting*/
				39 00 00 40 00 00 07 D0 09 30 08 1C 0A 30
				39 00 00 40 00 00 06 F0 55 AA 52 08 00
				39 00 00 40 00 00 02 6F 4C
				39 00 00 40 00 00 03 DF 05 20
				/*FPR center postion x[11:0], y[11:0]*/
				39 00 00 40 00 00 06 88 01 02 62 09 8C
				/*alpha for AA*/
				39 00 00 00 00 00 04 87 25 11 11
			];
			mi,mdss-dsi-local-hbm-normal-white-1000nit-command-update = <0x87 9 3>, <0xD0 4 6>, <0xDF 7 2>;
			mi,mdss-dsi-local-hbm-normal-white-1000nit-command-state = "dsi_hs_mode";

			mi,mdss-dsi-local-hbm-hlpm-white-1000nit-command = [
				/* AOD off */
				15 00 00 00 00 00 02 65 00
				15 00 00 00 00 00 02 38 00
				39 00 00 00 00 00 07 51 00 00 00 00 03 FF
				15 00 00 00 00 00 02 2C 00
				/* Local HBM setting*/
				39 00 00 40 00 00 06 F0 55 AA 52 08 00
				39 00 00 40 00 00 02 6F 31
				39 00 00 40 00 00 02 DF 22
				39 00 00 40 00 00 06 F0 55 AA 52 08 02
				/*FPR area RGB[11:0] setting*/
				39 00 00 40 00 00 07 D0 09 30 08 1C 0A 30
				39 00 00 40 00 00 06 F0 55 AA 52 08 00
				39 00 00 40 00 00 02 6F 4C
				39 00 00 40 00 00 03 DF 05 20
				/*FPR center postion x[11:0], y[11:0]*/
				39 00 00 40 00 00 06 88 01 02 62 09 8C
				/*alpha for AA*/
				39 00 00 00 00 00 04 87 25 11 11
			];
			mi,mdss-dsi-local-hbm-hlpm-white-1000nit-command-update = <0x87 13 3>, <0xD0 8 6>;
			mi,mdss-dsi-local-hbm-hlpm-white-1000nit-command-state = "dsi_hs_mode";

			mi,mdss-dsi-local-hbm-normal-white-110nit-command = [
				39 00 00 40 00 00 06 F0 55 AA 52 08 00
				39 00 00 40 00 00 02 6F 31
				39 00 00 40 00 00 02 DF 22
				39 00 00 40 00 00 06 F0 55 AA 52 08 02
				/*FPR area RGB[11:0] setting*/
				39 00 00 40 00 00 07 D0 06 55 05 CC 07 1F
				39 00 00 40 00 00 06 F0 55 AA 52 08 00
				39 00 00 40 00 00 02 6F 4C
				39 00 00 40 00 00 03 DF 05 20
				/*FPR center postion x[11:0], y[11:0]*/
				39 00 00 40 00 00 06 88 01 02 62 09 8C
				/*alpha for AA*/
				39 00 00 00 00 00 04 87 25 11 11
			];
			mi,mdss-dsi-local-hbm-normal-white-110nit-command-update  = <0x87 9 3>, <0xD0 4 6>;
			mi,mdss-dsi-local-hbm-normal-white-110nit-command-state = "dsi_hs_mode";

			mi,mdss-dsi-local-hbm-hlpm-white-110nit-command = [
				/* AOD off */
				15 00 00 00 00 00 02 65 00
				15 00 00 00 00 00 02 38 00
				39 00 00 00 00 00 07 51 00 00 00 00 01 FF
				15 00 00 00 00 00 02 2C 00
				/* Local HBM setting*/
				39 00 00 40 00 00 06 F0 55 AA 52 08 00
				39 00 00 40 00 00 02 6F 31
				39 00 00 40 00 00 02 DF 22
				39 00 00 40 00 00 06 F0 55 AA 52 08 02
				/*FPR area RGB[11:0] setting*/
				39 00 00 40 00 00 07 D0 06 55 05 CC 07 1F
				39 00 00 40 00 00 06 F0 55 AA 52 08 00
				39 00 00 40 00 00 02 6F 4C
				39 00 00 40 00 00 03 DF 05 20
				/*FPR center postion x[11:0], y[11:0]*/
				39 00 00 40 00 00 06 88 01 02 62 09 8C
				/*alpha for AA*/
				39 00 00 00 00 00 04 87 25 11 11
			];
			mi,mdss-dsi-local-hbm-hlpm-white-110nit-command-update = <0x87 13 3>, <0xD0 8 6>;
			mi,mdss-dsi-local-hbm-hlpm-white-110nit-command-state = "dsi_hs_mode";

			mi,mdss-dsi-local-hbm-normal-green-500nit-command = [
				39 00 00 00 00 00 06 F0 55 AA 52 08 00
				39 00 00 40 00 00 02 6F 31
				39 00 00 40 00 00 02 DF 22
				39 00 00 40 00 00 06 F0 55 AA 52 08 02
				/*FPR area RGB[11:0] setting*/
				39 00 00 40 00 00 07 D0 00 00 07 BC 00 00
				39 00 00 00 00 00 06 F0 55 AA 52 08 00
				39 00 00 40 00 00 02 6F 4C
				39 00 00 40 00 00 03 DF 05 20
				/*FPR center postion x[11:0], y[11:0]*/
				39 00 00 40 00 00 06 88 01 02 62 09 8C
				/*alpha for AA*/
				39 00 00 00 00 00 04 87 25 11 11
			];
			/* <mipi_address  update_index  update_length> */
			mi,mdss-dsi-local-hbm-normal-green-500nit-command-update = <0x87 9 3>, <0xDF 7 2>;
			mi,mdss-dsi-local-hbm-normal-green-500nit-command-state = "dsi_lp_mode";

			mi,mdss-dsi-local-hbm-off-to-normal-command = [
				39 00 00 40 00 00 03 51 07 FF
				39 00 00 00 00 00 02 87 00
			];
			mi,mdss-dsi-local-hbm-off-to-normal-command-update = <0x51 0 2>;
			mi,mdss-dsi-local-hbm-off-to-normal-command-state = "dsi_hs_mode";

			mi,mdss-dsi-local-hbm-off-to-hbm-command= [
				39 00 00 00 00 00 03 51 07 FF
				39 00 00 00 00 00 02 87 00
			];
			mi,mdss-dsi-local-hbm-off-to-hbm-command-update = <0x51 0 2>;
			mi,mdss-dsi-local-hbm-off-to-hbm-command-state = "dsi_hs_mode";

			mi,mdss-dsi-local-hbm-off-to-hlpm-command = [
				/* Lhbm off */
				39 00 00 00 00 00 03 51 00 00
				39 00 00 00 00 00 02 87 00
				/* Aod hbm */
				39 00 00 40 00 00 07 51 00 00 00 00 03 FF
				15 00 00 40 00 00 02 39 00
				15 00 00 40 00 00 02 65 01
				15 00 00 00 00 00 02 2C 00
			];
			mi,mdss-dsi-local-hbm-off-to-hlpm-command-state = "dsi_hs_mode";

			mi,mdss-dsi-local-hbm-off-to-llpm-command = [
				/* Lhbm off */
				39 00 00 00 00 00 03 51 00 00
				39 00 00 00 00 00 02 87 00
				/* Aod lbm */
				15 00 00 40 00 00 02 6F 04
				39 00 00 40 00 00 03 51 01 FF
				15 00 00 40 00 00 02 39 00
				15 00 00 40 00 00 02 65 01
				15 00 00 00 00 00 02 2C 00
			];
			mi,mdss-dsi-local-hbm-off-to-llpm-command-state = "dsi_hs_mode";

			mi,mdss-dsi-doze-hbm-command = [
				/* Turnoff osc trim */
				39 00 00 40 00 00 06 F0 55 AA 52 08 01
				15 00 00 40 00 00 02 C3 00
				/* ERR Flag output VDDI */
				39 00 00 40 00 00 06 F0 55 AA 52 08 00
				39 00 00 40 00 00 02 6F 01
				39 00 00 40 00 00 02 BE 41
				/* AOD Mode on*/
				39 00 00 40 00 00 07 51 00 00 00 00 03 FF
				15 00 00 40 00 00 02 39 00
				15 00 00 40 00 00 02 65 01
				15 00 00 00 00 00 02 2C 00
			];
			mi,mdss-dsi-doze-hbm-command-state = "dsi_lp_mode";
			mi,mdss-dsi-doze-lbm-command = [
				/* Turnoff osc trim */
				39 00 00 40 00 00 06 F0 55 AA 52 08 01
				15 00 00 40 00 00 02 C3 00
				/* ERR Flag output VDDI */
				39 00 00 40 00 00 06 F0 55 AA 52 08 00
				39 00 00 40 00 00 02 6F 01
				39 00 00 40 00 00 02 BE 41
				/*AOD Mode on*/
				15 00 00 40 00 00 02 6F 04
				39 00 00 40 00 00 03 51 01 FF
				15 00 00 40 00 00 02 39 00
				15 00 00 40 00 00 02 65 01
				15 00 00 00 00 00 02 2C 00
			];
			mi,mdss-dsi-doze-lbm-command-state = "dsi_lp_mode";
			mi,mdss-dsi-doze-hbm-nolp-command = [
				/* Enable osc trim */
				39 00 00 00 00 00 06 F0 55 AA 52 08 01
				15 00 00 00 00 00 02 C3 DD
				/*AOD Mode off*/
				15 00 00 00 00 00 02 65 00
				15 00 00 00 00 00 02 38 00
				39 00 00 00 00 00 07 51 00 00 00 00 03 FF
				15 00 00 00 00 00 02 2C 00
				/* ERR Flag enable */
				39 00 00 00 00 00 06 F0 55 AA 52 08 00
				39 00 00 00 00 00 02 6F 01
				39 00 00 00 00 00 02 BE 45
			];
			mi,mdss-dsi-doze-hbm-nolp-command-state = "dsi_lp_mode";
			mi,mdss-dsi-doze-lbm-nolp-command = [
				/* Enable osc trim */
				39 00 00 00 00 00 06 F0 55 AA 52 08 01
				15 00 00 00 00 00 02 C3 DD
				/*AOD Mode off*/
				15 00 00 00 00 00 02 65 00
				15 00 00 00 00 00 02 38 00
				39 00 00 00 00 00 07 51 00 00 00 00 01 FF
				15 00 00 00 00 00 02 2C 00
				/* ERR Flag enable */
				39 00 00 00 00 00 06 F0 55 AA 52 08 00
				39 00 00 00 00 00 02 6F 01
				39 00 00 00 00 00 02 BE 45
			];
			mi,mdss-dsi-doze-lbm-nolp-command-state = "dsi_lp_mode";

			mi,mdss-dsi-flat-mode-on-command = [
				15 00 00 00 00 00 02 5F 00
				15 00 00 00 00 00 02 2F 03
			];
			mi,mdss-dsi-flat-mode-on-command-state = "dsi_lp_mode";

			mi,mdss-dsi-flat-mode-off-command = [
				15 00 00 00 00 00 02 5F 01
				15 00 00 00 00 00 02 2F 00
			];
			mi,mdss-dsi-flat-mode-off-command-state = "dsi_lp_mode";

			mi,mdss-dsi-round-corner-on-command = [
				/* Page 07 */
				39 00 00 00 00 00 06 F0 55 AA 52 08 07
				/* Round on */
				39 00 00 00 00 00 02 C0 A1
			];
			mi,mdss-dsi-round-corner-on-command-state = "dsi_lp_mode";

			mi,mdss-dsi-round-corner-off-command = [
				/* Page 07 */
				39 00 00 00 00 00 06 F0 55 AA 52 08 07
				/* Round off */
				39 00 00 40 00 00 02 C0 07
				39 00 00 40 00 00 02 C1 00
				39 00 00 40 00 00 02 C2 00
				39 00 00 40 00 00 02 C3 00
				39 00 00 40 00 00 02 C4 00
				39 00 00 40 00 00 02 C5 00
				39 00 00 40 00 00 02 C6 00
				39 00 00 40 00 00 02 C7 00
				39 00 00 40 00 00 02 C8 00
				39 00 00 40 00 00 02 C9 00
				39 00 00 40 00 00 02 CA 00
				39 00 00 40 00 00 02 CB 00
				39 00 00 00 00 00 02 CC 00
			];
			mi,mdss-dsi-round-corner-off-command-state = "dsi_lp_mode";

			mi,mdss-dsi-dimming-8frame-command = [
				39 00 00 00 00 00 06 F0 55 AA 52 08 00
				15 00 00 00 00 00 02 6F 05
				39 00 00 00 00 00 03 B2 08 08
			];
			mi,mdss-dsi-dimming-8frame-command-state = "dsi_lp_mode";

			mi,mdss-dsi-dimming-4frame-command = [
				39 00 00 00 00 00 06 F0 55 AA 52 08 00
				15 00 00 00 00 00 02 6F 05
				39 00 00 00 00 00 03 B2 04 04
			];
			mi,mdss-dsi-dimming-4frame-command-state = "dsi_lp_mode";
		};

		timing@1{ /* 120 hz */
			/*<flat on gamma, flat off gamma>*/
			mi,mdss-flat-status-control-gamma-cfg = <0x05 0x02>;
			mi,mdss-dsi-dimmingon-command = [39 00 00 00 00 00 02 53 28];
			mi,mdss-dsi-dimmingon-command-state = "dsi_hs_mode";
			mi,mdss-dsi-dimmingoff-command = [39 00 00 00 00 00 02 53 20];
			mi,mdss-dsi-dimmingoff-command-state = "dsi_hs_mode";

			mi,mdss-dsi-hbm-fod-on-command = [
				39 00 00 00 00 00 05 51 0F FF 00 00];
			mi,mdss-dsi-hbm-fod-on-command-state = "dsi_lp_mode";
			mi,mdss-dsi-hbm-fod-off-command = [
				39 00 00 00 00 00 05 51 07 FF 00 00];
			mi,mdss-dsi-hbm-fod-off-command-state = "dsi_lp_mode";
			mi,mdss-dsi-hbm-fod-off-command-update = <0x51 0 2>;

			mi,mdss-dsi-local-hbm-normal-white-1000nit-command = [
				39 00 00 40 00 00 06 F0 55 AA 52 08 00
				39 00 00 40 00 00 02 6F 31
				39 00 00 40 00 00 02 DF 22
				39 00 00 40 00 00 06 F0 55 AA 52 08 02
				/*FPR area RGB[11:0] setting*/
				39 00 00 40 00 00 07 D0 09 30 08 1C 0A 30
				39 00 00 40 00 00 06 F0 55 AA 52 08 00
				39 00 00 40 00 00 02 6F 4C
				39 00 00 40 00 00 03 DF 05 20
				/*FPR center postion x[11:0], y[11:0]*/
				39 00 00 40 00 00 06 88 01 02 62 09 8C
				/*alpha for AA*/
				39 00 00 00 00 00 04 87 25 11 11
			];
			mi,mdss-dsi-local-hbm-normal-white-1000nit-command-update = <0x87 9 3>, <0xD0 4 6>, <0xDF 7 2>;
			mi,mdss-dsi-local-hbm-normal-white-1000nit-command-state = "dsi_hs_mode";

			mi,mdss-dsi-local-hbm-hlpm-white-1000nit-command = [
				/* AOD off */
				15 00 00 00 00 00 02 65 00
				15 00 00 00 00 00 02 38 00
				39 00 00 00 00 00 07 51 00 00 00 00 03 FF
				15 00 00 00 00 00 02 2C 00
				/* Local HBM setting*/
				39 00 00 40 00 00 06 F0 55 AA 52 08 00
				39 00 00 40 00 00 02 6F 31
				39 00 00 40 00 00 02 DF 22
				39 00 00 40 00 00 06 F0 55 AA 52 08 02
				/*FPR area RGB[11:0] setting*/
				39 00 00 40 00 00 07 D0 09 30 08 1C 0A 30
				39 00 00 40 00 00 06 F0 55 AA 52 08 00
				39 00 00 40 00 00 02 6F 4C
				39 00 00 40 00 00 03 DF 05 20
				/*FPR center postion x[11:0], y[11:0]*/
				39 00 00 40 00 00 06 88 01 02 62 09 8C
				/*alpha for AA*/
				39 00 00 00 00 00 04 87 25 11 11
			];
			mi,mdss-dsi-local-hbm-hlpm-white-1000nit-command-update = <0x87 13 3>, <0xD0 8 6>;
			mi,mdss-dsi-local-hbm-hlpm-white-1000nit-command-state = "dsi_hs_mode";

			mi,mdss-dsi-local-hbm-normal-white-110nit-command = [
				39 00 00 40 00 00 06 F0 55 AA 52 08 00
				39 00 00 40 00 00 02 6F 31
				39 00 00 40 00 00 02 DF 22
				39 00 00 40 00 00 06 F0 55 AA 52 08 02
				/*FPR area RGB[11:0] setting*/
				39 00 00 40 00 00 07 D0 06 55 05 CC 07 1F
				39 00 00 40 00 00 06 F0 55 AA 52 08 00
				39 00 00 40 00 00 02 6F 4C
				39 00 00 40 00 00 03 DF 05 20
				/*FPR center postion x[11:0], y[11:0]*/
				39 00 00 40 00 00 06 88 01 02 62 09 8C
				/*alpha for AA*/
				39 00 00 00 00 00 04 87 25 11 11
			];
			mi,mdss-dsi-local-hbm-normal-white-110nit-command-update  = <0x87 9 3>, <0xD0 4 6>;
			mi,mdss-dsi-local-hbm-normal-white-110nit-command-state = "dsi_hs_mode";

			mi,mdss-dsi-local-hbm-hlpm-white-110nit-command = [
				/* AOD off */
				15 00 00 00 00 00 02 65 00
				15 00 00 00 00 00 02 38 00
				39 00 00 00 00 00 07 51 00 00 00 00 01 FF
				15 00 00 00 00 00 02 2C 00
				/* Local HBM setting*/
				39 00 00 40 00 00 06 F0 55 AA 52 08 00
				39 00 00 40 00 00 02 6F 31
				39 00 00 40 00 00 02 DF 22
				39 00 00 40 00 00 06 F0 55 AA 52 08 02
				/*FPR area RGB[11:0] setting*/
				39 00 00 40 00 00 07 D0 06 55 05 CC 07 1F
				39 00 00 40 00 00 06 F0 55 AA 52 08 00
				39 00 00 40 00 00 02 6F 4C
				39 00 00 40 00 00 03 DF 05 20
				/*FPR center postion x[11:0], y[11:0]*/
				39 00 00 40 00 00 06 88 01 02 62 09 8C
				/*alpha for AA*/
				39 00 00 00 00 00 04 87 25 11 11
			];
			mi,mdss-dsi-local-hbm-hlpm-white-110nit-command-update = <0x87 13 3>, <0xD0 8 6>;
			mi,mdss-dsi-local-hbm-hlpm-white-110nit-command-state = "dsi_hs_mode";

			mi,mdss-dsi-local-hbm-normal-green-500nit-command = [
				39 00 00 00 00 00 06 F0 55 AA 52 08 00
				39 00 00 40 00 00 02 6F 31
				39 00 00 40 00 00 02 DF 22
				39 00 00 40 00 00 06 F0 55 AA 52 08 02
				/*FPR area RGB[11:0] setting*/
				39 00 00 40 00 00 07 D0 00 00 07 BC 00 00
				39 00 00 00 00 00 06 F0 55 AA 52 08 00
				39 00 00 40 00 00 02 6F 4C
				39 00 00 40 00 00 03 DF 05 20
				/*FPR center postion x[11:0], y[11:0]*/
				39 00 00 40 00 00 06 88 01 02 62 09 8C
				/*alpha for AA*/
				39 00 00 00 00 00 04 87 25 11 11
			];
			/* <mipi_address  update_index  update_length> */
			mi,mdss-dsi-local-hbm-normal-green-500nit-command-update = <0x87 9 3>, <0xDF 7 2>;
			mi,mdss-dsi-local-hbm-normal-green-500nit-command-state = "dsi_lp_mode";

			mi,mdss-dsi-local-hbm-off-to-normal-command = [
				39 00 00 40 00 00 03 51 07 FF
				39 00 00 00 00 00 02 87 00
			];
			mi,mdss-dsi-local-hbm-off-to-normal-command-update = <0x51 0 2>;
			mi,mdss-dsi-local-hbm-off-to-normal-command-state = "dsi_hs_mode";

			mi,mdss-dsi-local-hbm-off-to-hbm-command= [
				39 00 00 00 00 00 03 51 07 FF
				39 00 00 00 00 00 02 87 00
			];
			mi,mdss-dsi-local-hbm-off-to-hbm-command-update = <0x51 0 2>;
			mi,mdss-dsi-local-hbm-off-to-hbm-command-state = "dsi_hs_mode";

			mi,mdss-dsi-local-hbm-off-to-hlpm-command = [
				/* Lhbm off */
				39 00 00 00 00 00 03 51 00 00
				39 00 00 00 00 00 02 87 00
				/* Aod hbm */
				39 00 00 40 00 00 07 51 00 00 00 00 03 FF
				15 00 00 40 00 00 02 39 00
				15 00 00 40 00 00 02 65 01
				15 00 00 00 00 00 02 2C 00
			];
			mi,mdss-dsi-local-hbm-off-to-hlpm-command-state = "dsi_hs_mode";

			mi,mdss-dsi-local-hbm-off-to-llpm-command = [
				/* Lhbm off */
				39 00 00 00 00 00 03 51 00 00
				39 00 00 00 00 00 02 87 00
				/* Aod lbm */
				15 00 00 40 00 00 02 6F 04
				39 00 00 40 00 00 03 51 01 FF
				15 00 00 40 00 00 02 39 00
				15 00 00 40 00 00 02 65 01
				15 00 00 00 00 00 02 2C 00
			];
			mi,mdss-dsi-local-hbm-off-to-llpm-command-state = "dsi_hs_mode";

			mi,mdss-dsi-doze-hbm-command = [
				/* Turnoff osc trim */
				39 00 00 40 00 00 06 F0 55 AA 52 08 01
				15 00 00 40 00 00 02 C3 00
				/* ERR Flag output VDDI */
				39 00 00 40 00 00 06 F0 55 AA 52 08 00
				39 00 00 40 00 00 02 6F 01
				39 00 00 40 00 00 02 BE 41
				/*AOD Mode on*/
				39 00 00 40 00 00 07 51 00 00 00 00 03 FF
				15 00 00 40 00 00 02 39 00
				15 00 00 40 00 00 02 65 01
				15 00 00 00 00 00 02 2C 00
			];
			mi,mdss-dsi-doze-hbm-command-state = "dsi_lp_mode";
			mi,mdss-dsi-doze-lbm-command = [
				/* Turnoff osc trim */
				39 00 00 40 00 00 06 F0 55 AA 52 08 01
				15 00 00 40 00 00 02 C3 00
				/* ERR Flag output VDDI */
				39 00 00 40 00 00 06 F0 55 AA 52 08 00
				39 00 00 40 00 00 02 6F 01
				39 00 00 40 00 00 02 BE 41
				/*AOD Mode on*/
				15 00 00 40 00 00 02 6F 04
				39 00 00 40 00 00 03 51 01 FF
				15 00 00 40 00 00 02 39 00
				15 00 00 40 00 00 02 65 01
				15 00 00 00 00 00 02 2C 00
			];
			mi,mdss-dsi-doze-lbm-command-state = "dsi_lp_mode";
			mi,mdss-dsi-doze-hbm-nolp-command = [
				/* Enable osc trim */
				39 00 00 00 00 00 06 F0 55 AA 52 08 01
				15 00 00 00 00 00 02 C3 DD
				/*AOD Mode off*/
				15 00 00 00 00 00 02 65 00
				15 00 00 00 00 00 02 38 00
				39 00 00 00 00 00 07 51 00 00 00 00 03 FF
				15 00 00 00 00 00 02 2C 00
				/* ERR Flag enable */
				39 00 00 00 00 00 06 F0 55 AA 52 08 00
				39 00 00 00 00 00 02 6F 01
				39 00 00 00 00 00 02 BE 45
			];
			mi,mdss-dsi-doze-hbm-nolp-command-state = "dsi_lp_mode";
			mi,mdss-dsi-doze-lbm-nolp-command = [
				/* Enable osc trim */
				39 00 00 00 00 00 06 F0 55 AA 52 08 01
				15 00 00 00 00 00 02 C3 DD
				/*AOD Mode off*/
				15 00 00 00 00 00 02 65 00
				15 00 00 00 00 00 02 38 00
				39 00 00 00 00 00 07 51 00 00 00 00 01 FF
				15 00 00 00 00 00 02 2C 00
				/* ERR Flag enable */
				39 00 00 00 00 00 06 F0 55 AA 52 08 00
				39 00 00 00 00 00 02 6F 01
				39 00 00 00 00 00 02 BE 45
			];
			mi,mdss-dsi-doze-lbm-nolp-command-state = "dsi_lp_mode";

			mi,mdss-dsi-flat-mode-on-command = [
				15 00 00 00 00 00 02 5F 00
				15 00 00 00 00 00 02 2F 05
			];
			mi,mdss-dsi-flat-mode-on-command-state = "dsi_lp_mode";

			mi,mdss-dsi-flat-mode-off-command = [
				15 00 00 00 00 00 02 5F 01
				15 00 00 00 00 00 02 2F 02
			];
			mi,mdss-dsi-flat-mode-off-command-state = "dsi_lp_mode";

			mi,mdss-dsi-round-corner-on-command = [
				/* Page 07 */
				39 00 00 00 00 00 06 F0 55 AA 52 08 07
				/* Round on */
				39 00 00 00 00 00 02 C0 A1
			];
			mi,mdss-dsi-round-corner-on-command-state = "dsi_lp_mode";

			mi,mdss-dsi-round-corner-off-command = [
				/* Page 07 */
				39 00 00 00 00 00 06 F0 55 AA 52 08 07
				/* Round off */
				39 00 00 40 00 00 02 C0 07
				39 00 00 40 00 00 02 C1 00
				39 00 00 40 00 00 02 C2 00
				39 00 00 40 00 00 02 C3 00
				39 00 00 40 00 00 02 C4 00
				39 00 00 40 00 00 02 C5 00
				39 00 00 40 00 00 02 C6 00
				39 00 00 40 00 00 02 C7 00
				39 00 00 40 00 00 02 C8 00
				39 00 00 40 00 00 02 C9 00
				39 00 00 40 00 00 02 CA 00
				39 00 00 40 00 00 02 CB 00
				39 00 00 00 00 00 02 CC 00
			];
			mi,mdss-dsi-round-corner-off-command-state = "dsi_lp_mode";

			mi,mdss-dsi-dimming-8frame-command = [
				39 00 00 00 00 00 06 F0 55 AA 52 08 00
				15 00 00 00 00 00 02 6F 05
				39 00 00 00 00 00 03 B2 08 08
			];
			mi,mdss-dsi-dimming-8frame-command-state = "dsi_lp_mode";

			mi,mdss-dsi-dimming-4frame-command = [
				39 00 00 00 00 00 06 F0 55 AA 52 08 00
				15 00 00 00 00 00 02 6F 05
				39 00 00 00 00 00 03 B2 04 04
			];
			mi,mdss-dsi-dimming-4frame-command-state = "dsi_lp_mode";

		};

		timing@2{ /* 90 hz */
			/*<flat on gamma, flat off gamma>*/
			mi,mdss-flat-status-control-gamma-cfg = <0x04 0x01>;
			mi,mdss-dsi-dimmingon-command = [39 00 00 00 00 00 02 53 28];
			mi,mdss-dsi-dimmingon-command-state = "dsi_hs_mode";
			mi,mdss-dsi-dimmingoff-command = [39 00 00 00 00 00 02 53 20];
			mi,mdss-dsi-dimmingoff-command-state = "dsi_hs_mode";

			mi,mdss-dsi-hbm-fod-on-command = [
				39 00 00 00 00 00 05 51 0F FF 00 00];
			mi,mdss-dsi-hbm-fod-on-command-state = "dsi_lp_mode";
			mi,mdss-dsi-hbm-fod-off-command = [
				39 00 00 00 00 00 05 51 07 FF 00 00];
			mi,mdss-dsi-hbm-fod-off-command-state = "dsi_lp_mode";
			mi,mdss-dsi-hbm-fod-off-command-update = <0x51 0 2>;

			mi,mdss-dsi-local-hbm-normal-white-1000nit-command = [
				/* Local HBM setting*/
				39 00 00 40 00 00 06 F0 55 AA 52 08 00
				39 00 00 40 00 00 02 6F 31
				39 00 00 40 00 00 02 DF 22
				39 00 00 40 00 00 06 F0 55 AA 52 08 02
				/*FPR area RGB[11:0] setting*/
				39 00 00 40 00 00 07 D0 09 30 08 1C 0A 30
				39 00 00 40 00 00 06 F0 55 AA 52 08 00
				39 00 00 40 00 00 02 6F 4C
				39 00 00 40 00 00 03 DF 05 20
				/*FPR center postion x[11:0], y[11:0]*/
				39 00 00 40 00 00 06 88 01 02 62 09 8C
				/*alpha for AA*/
				39 00 00 00 00 00 04 87 25 11 11
			];
			mi,mdss-dsi-local-hbm-normal-white-1000nit-command-update = <0x87 9 3>, <0xD0 4 6>, <0xDF 7 2>;
			mi,mdss-dsi-local-hbm-normal-white-1000nit-command-state = "dsi_hs_mode";

			mi,mdss-dsi-local-hbm-hlpm-white-1000nit-command = [
				/* AOD off */
				15 00 00 00 00 00 02 65 00
				15 00 00 00 00 00 02 38 00
				39 00 00 00 00 00 07 51 00 00 00 00 03 FF
				15 00 00 00 00 00 02 2C 00
				/* Local HBM setting*/
				39 00 00 40 00 00 06 F0 55 AA 52 08 00
				39 00 00 40 00 00 02 6F 31
				39 00 00 40 00 00 02 DF 22
				39 00 00 40 00 00 06 F0 55 AA 52 08 02
				/*FPR area RGB[11:0] setting*/
				39 00 00 40 00 00 07 D0 09 30 08 1C 0A 30
				39 00 00 40 00 00 06 F0 55 AA 52 08 00
				39 00 00 40 00 00 02 6F 4C
				39 00 00 40 00 00 03 DF 05 20
				/*FPR center postion x[11:0], y[11:0]*/
				39 00 00 40 00 00 06 88 01 02 62 09 8C
				/*alpha for AA*/
				39 00 00 00 00 00 04 87 25 11 11
			];
			mi,mdss-dsi-local-hbm-hlpm-white-1000nit-command-update = <0x87 13 3>, <0xD0 8 6>;
			mi,mdss-dsi-local-hbm-hlpm-white-1000nit-command-state = "dsi_hs_mode";

			mi,mdss-dsi-local-hbm-normal-white-110nit-command = [
				39 00 00 40 00 00 06 F0 55 AA 52 08 00
				39 00 00 40 00 00 02 6F 31
				39 00 00 40 00 00 02 DF 22
				39 00 00 40 00 00 06 F0 55 AA 52 08 02
				/*FPR area RGB[11:0] setting*/
				39 00 00 40 00 00 07 D0 06 55 05 CC 07 1F
				39 00 00 40 00 00 06 F0 55 AA 52 08 00
				39 00 00 40 00 00 02 6F 4C
				39 00 00 40 00 00 03 DF 05 20
				/*FPR center postion x[11:0], y[11:0]*/
				39 00 00 40 00 00 06 88 01 02 62 09 8C
				/*alpha for AA*/
				39 00 00 00 00 00 04 87 25 11 11
			];
			mi,mdss-dsi-local-hbm-normal-white-110nit-command-update  = <0x87 9 3>, <0xD0 4 6>;
			mi,mdss-dsi-local-hbm-normal-white-110nit-command-state = "dsi_hs_mode";

			mi,mdss-dsi-local-hbm-hlpm-white-110nit-command = [
				/* AOD off */
				15 00 00 00 00 00 02 65 00
				15 00 00 00 00 00 02 38 00
				39 00 00 00 00 00 07 51 00 00 00 00 01 FF
				15 00 00 00 00 00 02 2C 00
				/* Local HBM setting*/
				39 00 00 40 00 00 06 F0 55 AA 52 08 00
				39 00 00 40 00 00 02 6F 31
				39 00 00 40 00 00 02 DF 22
				39 00 00 40 00 00 06 F0 55 AA 52 08 02
				/*FPR area RGB[11:0] setting*/
				39 00 00 40 00 00 07 D0 06 55 05 CC 07 1F
				39 00 00 40 00 00 06 F0 55 AA 52 08 00
				39 00 00 40 00 00 02 6F 4C
				39 00 00 40 00 00 03 DF 05 20
				/*FPR center postion x[11:0], y[11:0]*/
				39 00 00 40 00 00 06 88 01 02 62 09 8C
				/*alpha for AA*/
				39 00 00 00 00 00 04 87 25 11 11
			];
			mi,mdss-dsi-local-hbm-hlpm-white-110nit-command-update = <0x87 13 3>, <0xD0 8 6>;
			mi,mdss-dsi-local-hbm-hlpm-white-110nit-command-state = "dsi_hs_mode";

			mi,mdss-dsi-local-hbm-normal-green-500nit-command = [
				39 00 00 00 00 00 06 F0 55 AA 52 08 00
				39 00 00 40 00 00 02 6F 31
				39 00 00 40 00 00 02 DF 22
				39 00 00 40 00 00 06 F0 55 AA 52 08 02
				/*FPR area RGB[11:0] setting*/
				39 00 00 40 00 00 07 D0 00 00 07 BC 00 00
				39 00 00 00 00 00 06 F0 55 AA 52 08 00
				39 00 00 40 00 00 02 6F 4C
				39 00 00 40 00 00 03 DF 05 20
				/*FPR center postion x[11:0], y[11:0]*/
				39 00 00 40 00 00 06 88 01 02 62 09 8C
				/*alpha for AA*/
				39 00 00 00 00 00 04 87 25 11 11
			];
			/* <mipi_address  update_index  update_length> */
			mi,mdss-dsi-local-hbm-normal-green-500nit-command-update = <0x87 9 3>, <0xDF 7 2>;
			mi,mdss-dsi-local-hbm-normal-green-500nit-command-state = "dsi_lp_mode";

			mi,mdss-dsi-local-hbm-off-to-normal-command = [
				39 00 00 40 00 00 03 51 07 FF
				39 00 00 00 00 00 02 87 00
			];
			mi,mdss-dsi-local-hbm-off-to-normal-command-update = <0x51 0 2>;
			mi,mdss-dsi-local-hbm-off-to-normal-command-state = "dsi_hs_mode";

			mi,mdss-dsi-local-hbm-off-to-hbm-command= [
				39 00 00 00 00 00 03 51 07 FF
				39 00 00 00 00 00 02 87 00
			];
			mi,mdss-dsi-local-hbm-off-to-hbm-command-update = <0x51 0 2>;
			mi,mdss-dsi-local-hbm-off-to-hbm-command-state = "dsi_hs_mode";

			mi,mdss-dsi-local-hbm-off-to-hlpm-command = [
				/* Lhbm off */
				39 00 00 00 00 00 03 51 00 00
				39 00 00 00 00 00 02 87 00
				/* Aod hbm */
				39 00 00 40 00 00 07 51 00 00 00 00 03 FF
				15 00 00 40 00 00 02 39 00
				15 00 00 40 00 00 02 65 01
				15 00 00 00 00 00 02 2C 00
			];
			mi,mdss-dsi-local-hbm-off-to-hlpm-command-state = "dsi_hs_mode";

			mi,mdss-dsi-local-hbm-off-to-llpm-command = [
				/* Lhbm off */
				39 00 00 00 00 00 03 51 00 00
				39 00 00 00 00 00 02 87 00
				/* Aod lbm */
				15 00 00 40 00 00 02 6F 04
				39 00 00 40 00 00 03 51 01 FF
				15 00 00 40 00 00 02 39 00
				15 00 00 40 00 00 02 65 01
				15 00 00 00 00 00 02 2C 00
			];
			mi,mdss-dsi-local-hbm-off-to-llpm-command-state = "dsi_hs_mode";

			mi,mdss-dsi-doze-hbm-command = [
				/* Turnoff osc trim */
				39 00 00 40 00 00 06 F0 55 AA 52 08 01
				15 00 00 40 00 00 02 C3 00
				/* ERR Flag output VDDI */
				39 00 00 40 00 00 06 F0 55 AA 52 08 00
				39 00 00 40 00 00 02 6F 01
				39 00 00 40 00 00 02 BE 41
				/*AOD Mode on*/
				39 00 00 40 00 00 07 51 00 00 00 00 03 FF
				15 00 00 40 00 00 02 39 00
				15 00 00 40 00 00 02 65 01
				15 00 00 00 00 00 02 2C 00
			];
			mi,mdss-dsi-doze-hbm-command-state = "dsi_lp_mode";
			mi,mdss-dsi-doze-lbm-command = [
				/* Turnoff osc trim */
				39 00 00 40 00 00 06 F0 55 AA 52 08 01
				15 00 00 40 00 00 02 C3 00
				/* ERR Flag output VDDI */
				39 00 00 40 00 00 06 F0 55 AA 52 08 00
				39 00 00 40 00 00 02 6F 01
				39 00 00 40 00 00 02 BE 41
				/*AOD Mode on*/
				15 00 00 40 00 00 02 6F 04
				39 00 00 40 00 00 03 51 01 FF
				15 00 00 40 00 00 02 39 00
				15 00 00 40 00 00 02 65 01
				15 00 00 00 00 00 02 2C 00
			];
			mi,mdss-dsi-doze-lbm-command-state = "dsi_lp_mode";
			mi,mdss-dsi-doze-hbm-nolp-command = [
				/* Enable osc trim */
				39 00 00 00 00 00 06 F0 55 AA 52 08 01
				15 00 00 00 00 00 02 C3 DD
				/*AOD Mode off*/
				15 00 00 00 00 00 02 65 00
				15 00 00 00 00 00 02 38 00
				39 00 00 00 00 00 07 51 00 00 00 00 03 FF
				15 00 00 00 00 00 02 2C 00
				/* ERR Flag enable */
				39 00 00 00 00 00 06 F0 55 AA 52 08 00
				39 00 00 00 00 00 02 6F 01
				39 00 00 00 00 00 02 BE 45
			];
			mi,mdss-dsi-doze-hbm-nolp-command-state = "dsi_lp_mode";
			mi,mdss-dsi-doze-lbm-nolp-command = [
				/* Enable osc trim */
				39 00 00 00 00 00 06 F0 55 AA 52 08 01
				15 00 00 00 00 00 02 C3 DD
				/*AOD Mode off*/
				15 00 00 00 00 00 02 65 00
				15 00 00 00 00 00 02 38 00
				39 00 00 00 00 00 07 51 00 00 00 00 01 FF
				15 00 00 00 00 00 02 2C 00
				/* ERR Flag enable */
				39 00 00 00 00 00 06 F0 55 AA 52 08 00
				39 00 00 00 00 00 02 6F 01
				39 00 00 00 00 00 02 BE 45
			];
			mi,mdss-dsi-doze-lbm-nolp-command-state = "dsi_lp_mode";

			mi,mdss-dsi-flat-mode-on-command = [
				15 00 00 00 00 00 02 5F 00
				15 00 00 00 00 00 02 2F 04
			];
			mi,mdss-dsi-flat-mode-on-command-state = "dsi_lp_mode";

			mi,mdss-dsi-flat-mode-off-command = [
				15 00 00 00 00 00 02 5F 01
				15 00 00 00 00 00 02 2F 01
			];
			mi,mdss-dsi-flat-mode-off-command-state = "dsi_lp_mode";

			mi,mdss-dsi-round-corner-on-command = [
				/* Page 07 */
				39 00 00 00 00 00 06 F0 55 AA 52 08 07
				/* Round on */
				39 00 00 00 00 00 02 C0 A1
			];
			mi,mdss-dsi-round-corner-on-command-state = "dsi_lp_mode";

			mi,mdss-dsi-round-corner-off-command = [
				/* Page 07 */
				39 00 00 00 00 00 06 F0 55 AA 52 08 07
				/* Round off */
				39 00 00 40 00 00 02 C0 07
				39 00 00 40 00 00 02 C1 00
				39 00 00 40 00 00 02 C2 00
				39 00 00 40 00 00 02 C3 00
				39 00 00 40 00 00 02 C4 00
				39 00 00 40 00 00 02 C5 00
				39 00 00 40 00 00 02 C6 00
				39 00 00 40 00 00 02 C7 00
				39 00 00 40 00 00 02 C8 00
				39 00 00 40 00 00 02 C9 00
				39 00 00 40 00 00 02 CA 00
				39 00 00 40 00 00 02 CB 00
				39 00 00 00 00 00 02 CC 00
			];
			mi,mdss-dsi-round-corner-off-command-state = "dsi_lp_mode";

			mi,mdss-dsi-dimming-8frame-command = [
				39 00 00 00 00 00 06 F0 55 AA 52 08 00
				15 00 00 00 00 00 02 6F 05
				39 00 00 00 00 00 03 B2 08 08
			];
			mi,mdss-dsi-dimming-8frame-command-state = "dsi_lp_mode";

			mi,mdss-dsi-dimming-4frame-command = [
				39 00 00 00 00 00 06 F0 55 AA 52 08 00
				15 00 00 00 00 00 02 6F 05
				39 00 00 00 00 00 03 B2 04 04
			];
			mi,mdss-dsi-dimming-4frame-command-state = "dsi_lp_mode";

		};
	};
};
